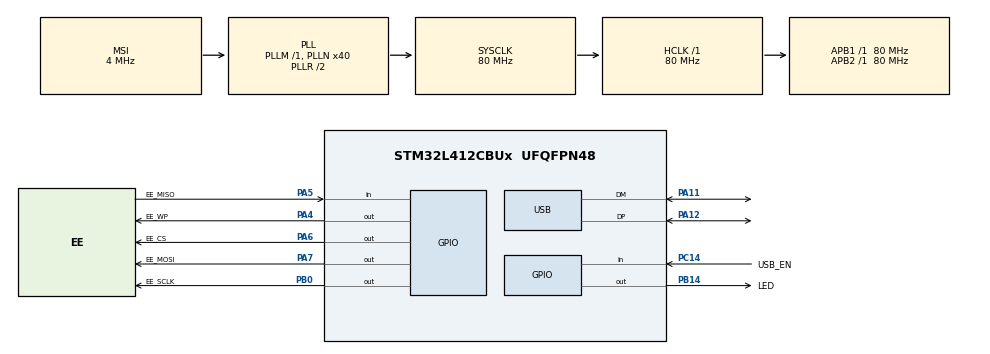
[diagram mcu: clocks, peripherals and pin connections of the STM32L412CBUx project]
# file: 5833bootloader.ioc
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Mcu.Family=STM32L4
Mcu.Name=STM32L412CBUx
Mcu.Package=UFQFPN48
NVIC.PriorityGroup=NVIC_PRIORITYGROUP_4
NVIC.USB_IRQn=true\:1\:0\:true\:false\:true\:false\:true
PA11.Mode=Device
PA11.Signal=USB_DM
PA12.Mode=Device
PA12.Signal=USB_DP
PA13\ (JTMS/SWDIO).Mode=Serial_Wire
PA13\ (JTMS/SWDIO).Signal=SYS_JTMS-SWDIO
PA14\ (JTCK/SWCLK).Mode=Serial_Wire
PA14\ (JTCK/SWCLK).Signal=SYS_JTCK-SWCLK
PA4.GPIO_Label=EE_WP
PA4.PinState=GPIO_PIN_SET
PA4.Signal=GPIO_Output
PA5.GPIO_Label=EE_MISO
PA5.Signal=GPIO_Input
PA6.GPIO_Label=EE_CS
PA6.Signal=GPIO_Output
PA7.GPIO_Label=EE_MOSI
PA7.GPIO_Speed=GPIO_SPEED_FREQ_HIGH
PA7.Signal=GPIO_Output
PB0.GPIO_Label=EE_SCLK
PB0.GPIO_Speed=GPIO_SPEED_FREQ_HIGH
PB0.Signal=GPIO_Output
PB14.GPIO_Label=LED
PB14.PinState=GPIO_PIN_SET
PB14.Signal=GPIO_Output
PC14-OSC32_IN\ (PC14).GPIO_Label=USB_EN
PC14-OSC32_IN\ (PC14).GPIO_PuPd=GPIO_PULLDOWN
PC14-OSC32_IN\ (PC14).Signal=GPIO_Input
ProjectManager.HeapSize=0x400
ProjectManager.StackSize=0x800
ProjectManager.TargetToolchain=Other Toolchains (GPDSC)
RCC.ADCFreq_Value=80000000
RCC.AHBFreq_Value=80000000
RCC.APB1Freq_Value=80000000
RCC.APB1TimFreq_Value=80000000
RCC.APB2Freq_Value=80000000
RCC.APB2TimFreq_Value=80000000
RCC.CK48CLockSelection=RCC_USBCLKSOURCE_HSI48
RCC.CortexFreq_Value=80000000
RCC.FLatency=FLASH_LATENCY_4
RCC.HCLKFreq_Value=80000000
RCC.HSE_VALUE=8000000
RCC.HSI48_VALUE=48000000
RCC.HSICalibrationValue=16
RCC.HSI_VALUE=16000000
RCC.LSE_VALUE=32768
RCC.MSI_VALUE=4000000
RCC.PLLN=40
RCC.SYSCLKFreq_VALUE=80000000
RCC.SYSCLKSource=RCC_SYSCLKSOURCE_PLLCLK
RCC.USBFreq_Value=48000000
RCC.VCOOutputFreq_Value=160000000
USB_DEVICE.CLASS_NAME_FS=CUSTOM_HID
USB_DEVICE.CONFIGURATION_STRING_CUSTOMHID_FS=MKToolConf
USB_DEVICE.INTERFACE_STRING_CUSTOMHID_FS=MKTool
USB_DEVICE.MANUFACTURER_STRING=WFDesign
USB_DEVICE.USBD_CUSTOMHID_OUTREPORT_BUF_SIZE=64
USB_DEVICE.USBD_CUSTOM_HID_REPORT_DESC_SIZE=34
USB_DEVICE.USBD_SELF_POWERED=0
USB_DEVICE.VirtualMode=CustomHid
USB_DEVICE.VirtualModeFS=Custom_Hid_FS
VP_USB_DEVICE_VS_USB_DEVICE_CUSTOM_HID_FS.Mode=CUSTOM_HID_FS
board=custom

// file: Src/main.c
/* USER CODE BEGIN Header */
/**
  ******************************************************************************
  * @file           : main.c
  * @brief          : Main program body
  ******************************************************************************
  * @attention
  *
  * <h2><center>&copy; Copyright (c) 2019 STMicroelectronics.
  * All rights reserved.</center></h2>
  *
  * This software component is licensed by ST under Ultimate Liberty license
  * SLA0044, the "License"; You may not use this file except in compliance with
  * the License. You may obtain a copy of the License at:
  *                             www.st.com/SLA0044
  *
  ******************************************************************************
  */
/* USER CODE END Header */

#include "main.h"
#include "usb_device.h"
#include "gpio.h"

/* USER CODE BEGIN Includes */
#include "wfSys.h"
#include "SimSPI.h"
#include "SPIROM.h"
#include "Variables.h"
/* USER CODE END Includes */

void SystemClock_Config(void);

int main(void)
{
  /* USER CODE BEGIN 1 */
	uint8_t eedata[16];
	uint32_t i;
  /* USER CODE END 1 */

  /* MCU Configuration--------------------------------------------------------*/

  /* Reset of all peripherals, Initializes the Flash interface and the Systick. */
  HAL_Init();

  /* Configure the system clock */
  SystemClock_Config();

  /* Initialize all configured peripherals */
  MX_GPIO_Init();
  /* USER CODE BEGIN 2 */

  if(HAL_GPIO_ReadPin(USB_EN_GPIO_Port,USB_EN_Pin))
  {
	  wfDelay_init(80);
	  SimSPI2_Init();
	  SPIROM_Init();
	  MX_USB_DEVICE_Init();
	  ledFlash(500);
  }
  /* USER CODE END 2 */

  /* Infinite loop */
  while (1)
  {

  }
}

void SystemClock_Config(void)
{
  RCC_OscInitTypeDef RCC_OscInitStruct = {0};
  RCC_ClkInitTypeDef RCC_ClkInitStruct = {0};
  RCC_PeriphCLKInitTypeDef PeriphClkInit = {0};

  /** Configure the main internal regulator output voltage
  */
  if (HAL_PWREx_ControlVoltageScaling(PWR_REGULATOR_VOLTAGE_SCALE1) != HAL_OK)
  {
    Error_Handler();
  }
  /** Initializes the CPU, AHB and APB busses clocks
  */
  RCC_OscInitStruct.OscillatorType = RCC_OSCILLATORTYPE_HSI48|RCC_OSCILLATORTYPE_MSI;
  RCC_OscInitStruct.HSI48State = RCC_HSI48_ON;
  RCC_OscInitStruct.MSIState = RCC_MSI_ON;
  RCC_OscInitStruct.MSICalibrationValue = 0;
  RCC_OscInitStruct.MSIClockRange = RCC_MSIRANGE_6;
  RCC_OscInitStruct.PLL.PLLState = RCC_PLL_ON;
  RCC_OscInitStruct.PLL.PLLSource = RCC_PLLSOURCE_MSI;
  RCC_OscInitStruct.PLL.PLLM = 1;
  RCC_OscInitStruct.PLL.PLLN = 40;
  RCC_OscInitStruct.PLL.PLLQ = RCC_PLLQ_DIV2;
  RCC_OscInitStruct.PLL.PLLR = RCC_PLLR_DIV2;
  if (HAL_RCC_OscConfig(&RCC_OscInitStruct) != HAL_OK)
  {
    Error_Handler();
  }
  /** Initializes the CPU, AHB and APB busses clocks
  */
  RCC_ClkInitStruct.ClockType = RCC_CLOCKTYPE_HCLK|RCC_CLOCKTYPE_SYSCLK
                              |RCC_CLOCKTYPE_PCLK1|RCC_CLOCKTYPE_PCLK2;
  RCC_ClkInitStruct.SYSCLKSource = RCC_SYSCLKSOURCE_PLLCLK;
  RCC_ClkInitStruct.AHBCLKDivider = RCC_SYSCLK_DIV1;
  RCC_ClkInitStruct.APB1CLKDivider = RCC_HCLK_DIV1;
  RCC_ClkInitStruct.APB2CLKDivider = RCC_HCLK_DIV1;

  if (HAL_RCC_ClockConfig(&RCC_ClkInitStruct, FLASH_LATENCY_4) != HAL_OK)
  {
    Error_Handler();
  }
  PeriphClkInit.PeriphClockSelection = RCC_PERIPHCLK_USB;
  PeriphClkInit.UsbClockSelection = RCC_USBCLKSOURCE_HSI48;
  if (HAL_RCCEx_PeriphCLKConfig(&PeriphClkInit) != HAL_OK)
  {
    Error_Handler();
  }
}

void Error_Handler(void)
{
}

/************************ (C) COPYRIGHT STMicroelectronics *****END OF FILE****/
